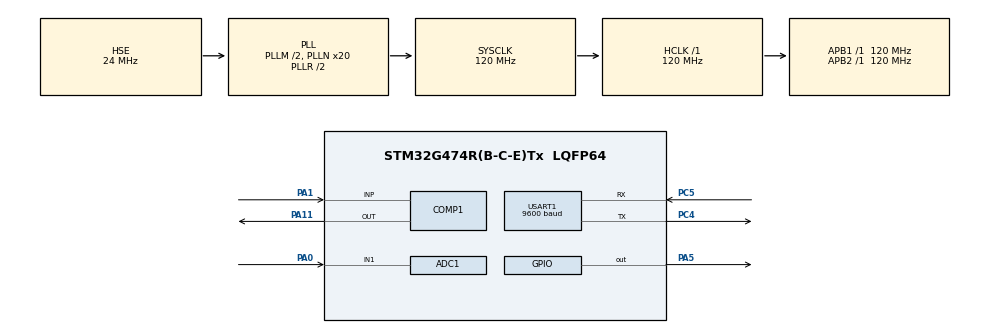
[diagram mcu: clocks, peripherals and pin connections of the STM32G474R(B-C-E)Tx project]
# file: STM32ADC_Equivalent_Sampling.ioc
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ADC1.Channel-1\#ChannelRegularConversion=ADC_CHANNEL_1
ADC1.NbrOfConversionFlag=1
ADC1.OffsetNumber-1\#ChannelRegularConversion=ADC_OFFSET_NONE
ADC1.Rank-1\#ChannelRegularConversion=1
ADC1.SamplingTime-1\#ChannelRegularConversion=ADC_SAMPLETIME_2CYCLES_5
ADC1.master=1
COMP1.TriggerMode=COMP_TRIGGERMODE_IT_RISING
Mcu.Family=STM32G4
Mcu.Name=STM32G474R(B-C-E)Tx
Mcu.Package=LQFP64
NVIC.COMP1_2_3_IRQn=true\:0\:0\:false\:false\:true\:false\:true\:true
NVIC.PriorityGroup=NVIC_PRIORITYGROUP_4
NVIC.TIM3_IRQn=true\:0\:0\:false\:false\:true\:true\:true\:true
NVIC.TIM4_IRQn=true\:0\:0\:false\:false\:true\:true\:true\:true
PA0.Mode=IN1-Single-Ended
PA0.Signal=ADC1_IN1
PA1.Mode=INP
PA1.Signal=COMP1_INP
PA11.Mode=ExternalOutput
PA11.Signal=COMP1_OUT
PA13.Mode=Serial_Wire
PA13.Signal=SYS_JTMS-SWDIO
PA14.Mode=Serial_Wire
PA14.Signal=SYS_JTCK-SWCLK
PA5.Signal=GPIO_Output
PC4.Mode=Asynchronous
PC4.Signal=USART1_TX
PC5.Mode=Asynchronous
PC5.Signal=USART1_RX
PF0-OSC_IN.Mode=HSE-External-Oscillator
PF0-OSC_IN.Signal=RCC_OSC_IN
PF1-OSC_OUT.Mode=HSE-External-Oscillator
PF1-OSC_OUT.Signal=RCC_OSC_OUT
ProjectManager.HeapSize=0x200
ProjectManager.StackSize=0x400
ProjectManager.TargetToolchain=MDK-ARM V5.32
RCC.ADC12Freq_Value=120000000
RCC.ADC345Freq_Value=120000000
RCC.AHBFreq_Value=120000000
RCC.APB1Freq_Value=120000000
RCC.APB1TimFreq_Value=120000000
RCC.APB2Freq_Value=120000000
RCC.APB2TimFreq_Value=120000000
RCC.CortexFreq_Value=120000000
RCC.EXTERNAL_CLOCK_VALUE=12288000
RCC.HCLKFreq_Value=120000000
RCC.HSE_VALUE=24000000
RCC.HSI48_VALUE=48000000
RCC.HSI_VALUE=16000000
RCC.LSE_VALUE=32768
RCC.PLLM=RCC_PLLM_DIV2
RCC.PLLN=20
RCC.PLLSourceVirtual=RCC_PLLSOURCE_HSE
RCC.SYSCLKFreq_VALUE=120000000
RCC.SYSCLKSource=RCC_SYSCLKSOURCE_PLLCLK
RCC.USBFreq_Value=120000000
RCC.VCOOutputFreq_Value=240000000
TIM3.PeriodNoDither=50000-1
TIM3.Prescaler=1200-1
TIM4.PeriodNoDither=100-1
TIM4.Prescaler=1200-1
USART1.BaudRate=9600
USART1.VirtualMode-Asynchronous=VM_ASYNC
VP_COMP1_VS_DAC1OUT1.Mode=INM_DAC1OUT1
VP_DAC1_VS_DACI1.Mode=DAC_OUT1_Int
VP_SYS_VS_DBSignals.Mode=DisableDeadBatterySignals
VP_TIM3_VS_ClockSourceINT.Mode=Internal
VP_TIM4_VS_ClockSourceINT.Mode=Internal
board=custom

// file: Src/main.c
/* USER CODE BEGIN Header */
/**
  ******************************************************************************
  * @file           : main.c
  * @brief          : Main program body
  ******************************************************************************
  * @attention
  *
  * Copyright (c) 2024 STMicroelectronics.
  * All rights reserved.
  *
  * This software is licensed under terms that can be found in the LICENSE file
  * in the root directory of this software component.
  * If no LICENSE file comes with this software, it is provided AS-IS.
  *
  ******************************************************************************
  */
/* USER CODE END Header */
#include "main.h"
#include "adc.h"
#include "comp.h"
#include "dac.h"
#include "tim.h"
#include "usart.h"
#include "gpio.h"

/* USER CODE BEGIN Includes */
#include "LED.h"
#include "my_adc.h"
#include "interrupt.h"
#include "stdio.h"
/* USER CODE END Includes */

void SystemClock_Config(void);

int main(void)
{

  /* MCU Configuration--------------------------------------------------------*/

  /* Reset of all peripherals, Initializes the Flash interface and the Systick. */
  HAL_Init();

  /* Configure the system clock */
  SystemClock_Config();

  /* Initialize all configured peripherals */
  MX_GPIO_Init();
  MX_TIM3_Init();
  MX_ADC1_Init();
  MX_COMP1_Init();
  MX_DAC1_Init();
  MX_USART1_UART_Init();
  MX_TIM4_Init();
  /* USER CODE BEGIN 2 */
  HAL_TIM_Base_Start_IT(&htim3); // ����������TIM3�ģ��ж�
  HAL_TIM_Base_Start_IT(&htim4); // ����������TIM4�ģ��ж�
  /* USER CODE END 2 */

  /* Infinite loop */
  while (1)
  {

  }
}

void SystemClock_Config(void)
{
  RCC_OscInitTypeDef RCC_OscInitStruct = {0};
  RCC_ClkInitTypeDef RCC_ClkInitStruct = {0};

  /** Configure the main internal regulator output voltage
  */
  HAL_PWREx_ControlVoltageScaling(PWR_REGULATOR_VOLTAGE_SCALE1);

  /** Initializes the RCC Oscillators according to the specified parameters
  * in the RCC_OscInitTypeDef structure.
  */
  RCC_OscInitStruct.OscillatorType = RCC_OSCILLATORTYPE_HSE;
  RCC_OscInitStruct.HSEState = RCC_HSE_ON;
  RCC_OscInitStruct.PLL.PLLState = RCC_PLL_ON;
  RCC_OscInitStruct.PLL.PLLSource = RCC_PLLSOURCE_HSE;
  RCC_OscInitStruct.PLL.PLLM = RCC_PLLM_DIV2;
  RCC_OscInitStruct.PLL.PLLN = 20;
  RCC_OscInitStruct.PLL.PLLP = RCC_PLLP_DIV2;
  RCC_OscInitStruct.PLL.PLLQ = RCC_PLLQ_DIV2;
  RCC_OscInitStruct.PLL.PLLR = RCC_PLLR_DIV2;
  if (HAL_RCC_OscConfig(&RCC_OscInitStruct) != HAL_OK)
  {
    Error_Handler();
  }

  /** Initializes the CPU, AHB and APB buses clocks
  */
  RCC_ClkInitStruct.ClockType = RCC_CLOCKTYPE_HCLK|RCC_CLOCKTYPE_SYSCLK
                              |RCC_CLOCKTYPE_PCLK1|RCC_CLOCKTYPE_PCLK2;
  RCC_ClkInitStruct.SYSCLKSource = RCC_SYSCLKSOURCE_PLLCLK;
  RCC_ClkInitStruct.AHBCLKDivider = RCC_SYSCLK_DIV1;
  RCC_ClkInitStruct.APB1CLKDivider = RCC_HCLK_DIV1;
  RCC_ClkInitStruct.APB2CLKDivider = RCC_HCLK_DIV1;

  if (HAL_RCC_ClockConfig(&RCC_ClkInitStruct, FLASH_LATENCY_3) != HAL_OK)
  {
    Error_Handler();
  }
}

void Error_Handler(void)
{
  __disable_irq();
  while (1)
  {
  }
}
